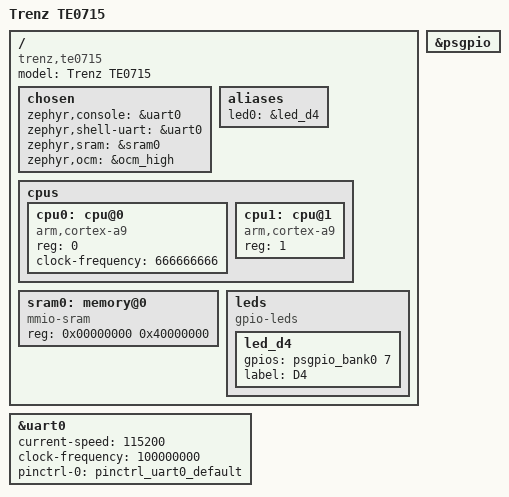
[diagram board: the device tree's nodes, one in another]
/dts-v1/;
#include <xilinx/zynq7000.dtsi>
#include <zephyr/dt-bindings/gpio/gpio.h>

#include "te0715-pinctrl.dtsi"
/* TODO: import other custom .dtsi files */

/ {
    model = "Trenz TE0715";
    compatible = "trenz,te0715", "xlnx,zynq-7000";

    #address-cells = <1>;
    #size-cells = <1>;

    chosen {
        zephyr,console = &uart0;
        zephyr,shell-uart = &uart0;
        zephyr,sram = &sram0;
        zephyr,ocm = &ocm_high;
    };

    aliases {
        led0 = &led_d4;
    };

    cpus {
        #address-cells = <1>;
        #size-cells = <0>;

        cpu0: cpu@0 {
            device_type = "cpu";
            compatible = "arm,cortex-a9";
            reg = <0>;
            /* TE0715 standard speed is 667 MHz */
            clock-frequency = <666666666>;
        };

        cpu1: cpu@1 {
            device_type = "cpu";
            compatible = "arm,cortex-a9";
            reg = <1>;
        };
    };

    /* 1 GB DDR3 SDRAM */    
    sram0: memory@0 {
        device_type = "memory";
        compatible = "mmio-sram";
        reg = <0x00000000 0x40000000>;
    };

    leds {
        compatible = "gpio-leds";

        /* Green user LED D4 on the module. MIO7 is muxed to GPIO by ps7_init. */
        led_d4: led_d4 {
            gpios = <&psgpio_bank0 7 GPIO_ACTIVE_HIGH>;
            label = "D4";
        };
    };
};

&uart0 {
    status = "okay";
    current-speed = <115200>;
    clock-frequency = <100000000>;
    pinctrl-0 = <&pinctrl_uart0_default>;
    pinctrl-names = "default";
};

&psgpio {
    status = "okay";
};
